# f29h85x_hsm_sm3_regs register map
Vendor: Texas Instruments
Peripheral module from a debugger description file (folder HSM).
Registers are 32-bit, read-write, no defined reset value unless marked. A register's access mark holds for its fields unless they carry their own. Offsets are as the file gives them; lines under a group give offsets from that group; [hi:lo] are bit positions; {n}, {i} and the like mark numbered series; 'fields as' and 'values as' point back to an identical list; <NAME> marks a mode.

## HSM_SM3 — HSM SM3 Registers
{0x0+4i} SM3_DATA_IN_{i} (i=0..15)
  [31:0] DATA_IN
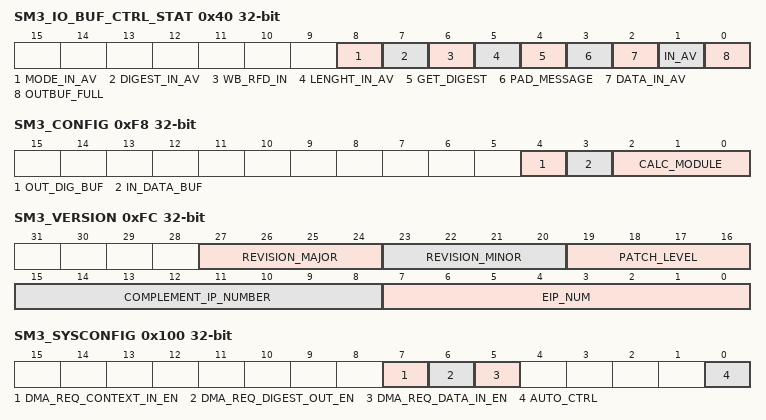
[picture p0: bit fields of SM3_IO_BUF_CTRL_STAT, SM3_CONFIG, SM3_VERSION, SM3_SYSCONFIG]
0x40 SM3_IO_BUF_CTRL_STAT access per field
  [8] MODE_IN_AV rw, [7] DIGEST_IN_AV rw, [6] WB_RFD_IN ro, [5] LENGHT_IN_AV rw, [4] GET_DIGEST rw, [3] PAD_MESSAGE rw, [2] DATA_IN_AV rw, [1] IN_AV rw, [0] OUTBUF_FULL rw
0x44 SM3_MODE_IN
  [0] NEW_HASH
0x48 SM3_LENGTH_IN_0
  [31:0] LENTH_IN_0
0x4C SM3_LENGTH_IN_1
  [31:0] LENTH_IN_1
{0x50+4i} SM3_DIGEST_IN_{i} (i=0..7)
  [31:0] DIGEST_IN
{0x70+4i} SM3_DIGEST_OUT_{i} ro (i=0..7)
  [31:0] DIGEST_OUT
0xF8 SM3_CONFIG ro
  [4] OUT_DIG_BUF, [3] IN_DATA_BUF, [2:0] CALC_MODULE
0xFC SM3_VERSION ro
  [27:24] REVISION_MAJOR, [23:20] REVISION_MINOR, [19:16] PATCH_LEVEL, [15:8] COMPLEMENT_IP_NUMBER, [7:0] EIP_NUM
0x100 SM3_SYSCONFIG — SM3 sysconfig registers
  [7] DMA_REQ_CONTEXT_IN_EN, [6] DMA_REQ_DIGEST_OUT_EN, [5] DMA_REQ_DATA_IN_EN, [0] AUTO_CTRL
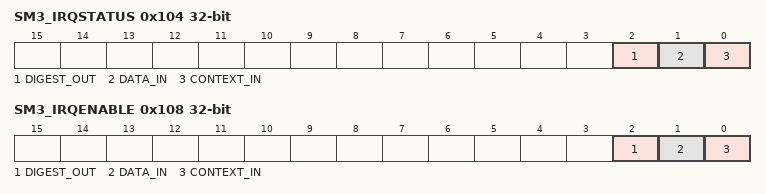
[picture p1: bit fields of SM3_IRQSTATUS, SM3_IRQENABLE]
0x104 SM3_IRQSTATUS — SM3 irqstatus registers
  [2] DIGEST_OUT, [1] DATA_IN, [0] CONTEXT_IN
0x108 SM3_IRQENABLE — SM3 irqenable registers
  [2] DIGEST_OUT, [1] DATA_IN, [0] CONTEXT_IN
